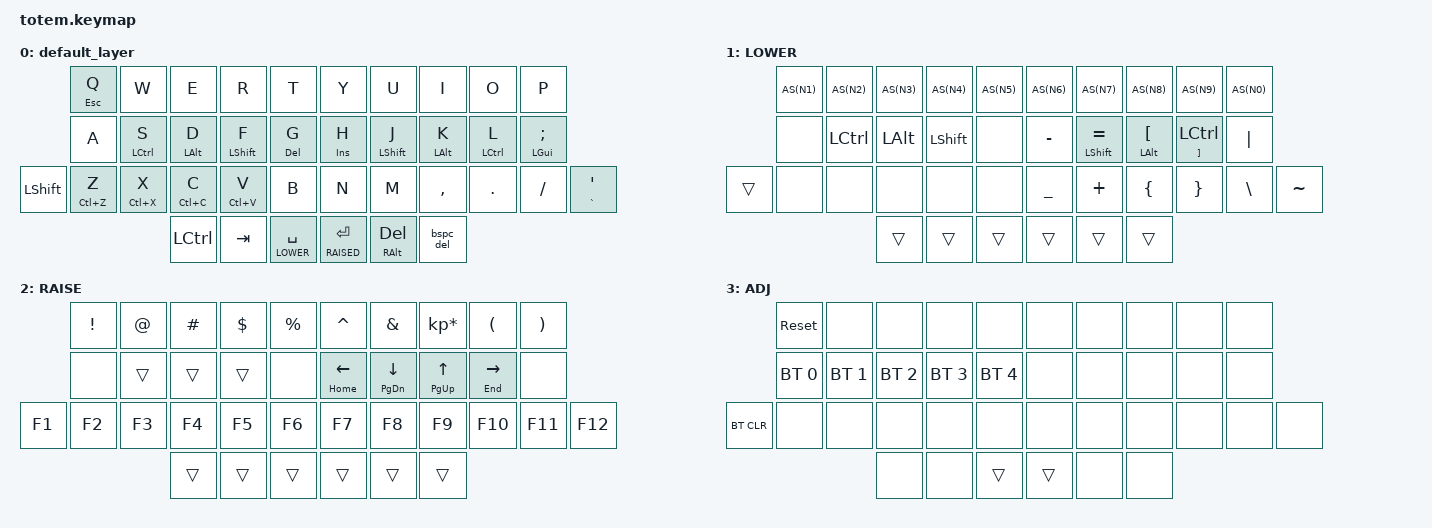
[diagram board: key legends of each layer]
//
//                                                        ▀▀▀▀▀     ▀▀▀▀▀          ▀▀█▀▀
//                                                        ▄▀▀▀▄  ▄  ▄▀▀▀▄  ▄  ▄▀▀▀▄  █  ▄▀▀▀▄
//                                                        █   █  █  █   █  █  █   █  █  █   █
//                                                         ▀▀▀   █   ▀▀▀   █   ▀▀▀   ▀   ▀▀▀
//                                                               █      ▄▄▄█▄▄▄    █   █  
//                                                               ▀      █  █  █     █▄█
//                                                             ▀▀▀▀▀    █  █  █      ▀
//                                                                      ▀  ▀  ▀
//
// ▄▄▄▄▄▄▄▄▄▄▄▄▄▄▄▄▄▄▄▄▄▄▄▄▄▄▄▄▄▄▄▄▄▄▄▄▄▄▄▄▄▄▄▄▄▄▄▄▄▄▄▄▄▄▄▄▄▄▄▄▄▄▄▄▄▄▄▄▄▄▄▄▄▄▄▄▄▄▄▄▄▄▄▄▄▄▄▄▄▄▄▄▄▄▄▄▄▄▄▄▄▄▄▄▄▄▄▄▄▄▄▄▄▄▄▄▄▄▄▄▄▄▄▄▄▄▄▄▄▄▄▄▄▄▄▄▄▄▄▄▄▄▄▄▄▄▄▄▄
       

#include <behaviors.dtsi>
#include <dt-bindings/zmk/keys.h>
#include <dt-bindings/zmk/bt.h>
#include "config.h"
#include "my-behaviours.dtsi"

/ {

     keymap {
                compatible = "zmk,keymap";
// ▄▄▄▄▄▄▄▄▄▄▄▄▄▄▄▄▄▄▄▄▄▄▄▄▄▄▄▄▄▄▄▄▄▄▄▄▄▄▄▄▄▄▄▄▄▄▄▄▄▄▄▄▄▄▄▄▄▄▄▄▄▄▄▄▄▄▄▄▄▄▄▄▄▄▄▄▄▄▄▄▄▄▄▄▄▄▄▄▄▄▄▄▄▄▄▄▄▄▄▄▄▄▄▄▄▄▄▄▄▄▄▄▄▄▄▄▄▄▄▄▄▄▄▄▄▄▄▄▄▄▄▄▄▄▄▄▄▄▄▄▄▄▄▄▄▄▄▄▄

                default_layer {
// ┏━━━━━━━━━━━━━━━━━━━━━━━━━━━━━━━━━━━━━━━┓
//label= "BASE"                              ;
// ┗━━━━━━━━━━━━━━━━━━━━━━━━━━━━━━━━━━━━━━━┛
//             ┏━━━━━━━━━━━┳━━━━━━━━━━━┳━━━━━━━━━━━┳━━━━━━━━━━━┳━━━━━━━━━━━┓   ┏━━━━━━━━━━━┳━━━━━━━━━━━┳━━━━━━━━━━━┳━━━━━━━━━━━┳━━━━━━━━━━━┓
//             ┃   Q/ESC   ┃     W     ┃     E     ┃     R     ┃     T     ┃   ┃     Y     ┃     U     ┃     I     ┃     O     ┃     P     ┃
//             ┣━━━━━━━━━━━╋━━━━━━━━━━━╋━━━━━━━━━━━╋━━━━━━━━━━━╋━━━━━━━━━━━┫   ┣━━━━━━━━━━━╋━━━━━━━━━━━╋━━━━━━━━━━━╋━━━━━━━━━━━╋━━━━━━━━━━━┫
//             ┃     A     ┃  S/LCTRL  ┃   D/LALT  ┃  F/LSHT   ┃     G     ┃   ┃   H/INS   ┃  J/LSHFT  ┃   K/LALT  ┃  L/LCTRL  ┃  ;/LGUI   ┃
// ┏━━━━━━━━━━━╋━━━━━━━━━━━╋━━━━━━━━━━━╋━━━━━━━━━━━╋━━━━━━━━━━━╋━━━━━━━━━━━┫   ┣━━━━━━━━━━━╋━━━━━━━━━━━╋━━━━━━━━━━━╋━━━━━━━━━━━╋━━━━━━━━━━━╋━━━━━━━━━━━┓
// ┃  LSHIFT   ┃     Z     ┃     X     ┃     C     ┃     V     ┃     B     ┃   ┃     N     ┃     M     ┃     ,     ┃     .     ┃     /     ┃    '/`    ┃
// ┗━━━━━━━━━━━┻━━━━━━━━━━━┻━━━━━━━━━━━╋━━━━━━━━━━━╋━━━━━━━━━━━╋━━━━━━━━━━━┫   ┣━━━━━━━━━━━╋━━━━━━━━━━━╋━━━━━━━━━━━╋━━━━━━━━━━━┻━━━━━━━━━━━┻━━━━━━━━━━━┛
//                                     ┃   LCTRL   ┃    TAB    ┃  SPC/LWR  ┃   ┃ ENTER/RSD ┃ DEL/RALT  ┃  BSPC/DEL ┃
//                                     ┗━━━━━━━━━━━┻━━━━━━━━━━━┻━━━━━━━━━━━┛   ┗━━━━━━━━━━━┻━━━━━━━━━━━┻━━━━━━━━━━━┛
 bindings = <
// ╷           ╷           ╷           ╷           ╷           ╷           ╷   ╷               ╷             ╷           ╷            ╷           ╷           ╷

                 &mt ESC Q   &kp W          &kp E       &kp R        &kp T           &kp Y        &kp U        &kp I        &kp O        &kp P       
                 &kp A       &mt LCTRL S    &mt LALT D  &mt LSHIFT F &mt DEL G       &mt INSERT H &mt LSHIFT J &mt LALT K   &mt LCTRL L  &ht LGUI SEMI    
     &kp LSHFT   &ht LC(Z) Z &ht LC(X) X    &ht LC(C) C &ht LC(V) V  &kp B           &kp N        &kp M        &kp COMMA    &kp DOT      &kp FSLH   &ht GRAVE SQT
                                            &kp LCTRL   &kp TAB      &lt LOWER SPACE &lt RAISED RET &mt RALT DEL &bspc_del
                        >;
                };

// ▄▄▄▄▄▄▄▄▄▄▄▄▄▄▄▄▄▄▄▄▄▄▄▄▄▄▄▄▄▄▄▄▄▄▄▄▄▄▄▄▄▄▄▄▄▄▄▄▄▄▄▄▄▄▄▄▄▄▄▄▄▄▄▄▄▄▄▄▄▄▄▄▄▄▄▄▄▄▄▄▄▄▄▄▄▄▄▄▄▄▄▄▄▄▄▄▄▄▄▄▄▄▄▄▄▄▄▄▄▄▄▄▄▄▄▄▄▄▄▄▄▄▄▄▄▄▄▄▄▄▄▄▄▄▄▄▄▄▄▄▄▄▄▄▄▄▄▄▄


                lower_layer {
// ┏━━━━━━━━━━━━━━━━━━━━━━━━━━━━━━━━━━━━━━━┓
label= "LOWER"                              ;
// ┗━━━━━━━━━━━━━━━━━━━━━━━━━━━━━━━━━━━━━━━┛
//             ┏━━━━━━━━━━━┳━━━━━━━━━━━┳━━━━━━━━━━━┳━━━━━━━━━━━┳━━━━━━━━━━━┓   ┏━━━━━━━━━━━┳━━━━━━━━━━━┳━━━━━━━━━━━┳━━━━━━━━━━━┳━━━━━━━━━━━┓
//             ┃     1     ┃     2     ┃      3    ┃     4     ┃     5     ┃   ┃     6     ┃     7     ┃     8     ┃     9     ┃     0     ┃
//             ┣━━━━━━━━━━━╋━━━━━━━━━━━╋━━━━━━━━━━━╋━━━━━━━━━━━╋━━━━━━━━━━━┫   ┣━━━━━━━━━━━╋━━━━━━━━━━━╋━━━━━━━━━━━╋━━━━━━━━━━━╋━━━━━━━━━━━┫
//             ┃     X     ┃   LCTRL   ┃    ALT    ┃   LSHT    ┃     X     ┃   ┃     -     ┃  =/LSHFT  ┃  [/LALT   ┃  ]/LCTRL  ┃     |     ┃
// ┏━━━━━━━━━━━╋━━━━━━━━━━━╋━━━━━━━━━━━╋━━━━━━━━━━━╋━━━━━━━━━━━╋━━━━━━━━━━━┫   ┣━━━━━━━━━━━╋━━━━━━━━━━━╋━━━━━━━━━━━╋━━━━━━━━━━━╋━━━━━━━━━━━╋━━━━━━━━━━━┓
// ┃           ┃     X     ┃    X      ┃     X     ┃     X     ┃     X     ┃   ┃     _     ┃     +     ┃     {     ┃     }     ┃     \     ┃     ~     ┃
// ┗━━━━━━━━━━━┻━━━━━━━━━━━┻━━━━━━━━━━━╋━━━━━━━━━━━╋━━━━━━━━━━━╋━━━━━━━━━━━┫   ┣━━━━━━━━━━━╋━━━━━━━━━━━╋━━━━━━━━━━━╋━━━━━━━━━━━┻━━━━━━━━━━━┻━━━━━━━━━━━┛
//                                     ┃           ┃           ┃           ┃   ┃           ┃           ┃           ┃
//                                     ┗━━━━━━━━━━━┻━━━━━━━━━━━┻━━━━━━━━━━━┛   ┗━━━━━━━━━━━┻━━━━━━━━━━━┻━━━━━━━━━━━┛
 bindings = <
// ╷           ╷           ╷                 ╷              ╷               ╷           ╷   ╷               ╷                ╷                  ╷                 ╷           ╷           ╷

                 AS(N1)         AS(N2)         AS(N3)        AS(N4)            AS(N5)            AS(N6)        AS(N7)            AS(N8)             AS(N9)           AS(N0)    
                 &none          &kp LCTRL      &kp LALT      &kp LSHIFT        &none             &kp MINUS     &mt LSHIFT EQUAL  &mt LALT LBKT      &mt RBKT LCTRL   &kp PIPE 
     &trans      &none          &none          &none         &none             &none             &kp UNDER     &kp PLUS          &kp LBRC           &kp RBRC         &kp BSLH   &kp TILDE
                                               &trans        &trans            &trans            &trans        &trans            &trans
                        >;
                };

// ▄▄▄▄▄▄▄▄▄▄▄▄▄▄▄▄▄▄▄▄▄▄▄▄▄▄▄▄▄▄▄▄▄▄▄▄▄▄▄▄▄▄▄▄▄▄▄▄▄▄▄▄▄▄▄▄▄▄▄▄▄▄▄▄▄▄▄▄▄▄▄▄▄▄▄▄▄▄▄▄▄▄▄▄▄▄▄▄▄▄▄▄▄▄▄▄▄▄▄▄▄▄▄▄▄▄▄▄▄▄▄▄▄▄▄▄▄▄▄▄▄▄▄▄▄▄▄▄▄▄▄▄▄▄▄▄▄▄▄▄▄▄▄▄▄▄▄▄▄


                raise_layer {
// ┏━━━━━━━━━━━━━━━━━━━━━━━━━━━━━━━━━━━━━━━┓
label= "RAISE"                               ;
// ┗━━━━━━━━━━━━━━━━━━━━━━━━━━━━━━━━━━━━━━━┛
//             ┏━━━━━━━━━━━┳━━━━━━━━━━━┳━━━━━━━━━━━┳━━━━━━━━━━━┳━━━━━━━━━━━┓   ┏━━━━━━━━━━━┳━━━━━━━━━━━┳━━━━━━━━━━━┳━━━━━━━━━━━┳━━━━━━━━━━━┓
//             ┃     !     ┃     @     ┃     #     ┃     $     ┃     %     ┃   ┃     ˆ     ┃     &     ┃     *     ┃     (     ┃     )     ┃
//             ┣━━━━━━━━━━━╋━━━━━━━━━━━╋━━━━━━━━━━━╋━━━━━━━━━━━╋━━━━━━━━━━━┫   ┣━━━━━━━━━━━╋━━━━━━━━━━━╋━━━━━━━━━━━╋━━━━━━━━━━━╋━━━━━━━━━━━┫
//             ┃     X     ┃           ┃           ┃           ┃    X      ┃   ┃   L/HOME  ┃   D/PGD   ┃   U/PGU   ┃  R/END    ┃     X     ┃
// ┏━━━━━━━━━━━╋━━━━━━━━━━━╋━━━━━━━━━━━╋━━━━━━━━━━━╋━━━━━━━━━━━╋━━━━━━━━━━━┫   ┣━━━━━━━━━━━╋━━━━━━━━━━━╋━━━━━━━━━━━╋━━━━━━━━━━━╋━━━━━━━━━━━╋━━━━━━━━━━━┓
// ┃    F1     ┃     F2    ┃    F3     ┃    F4     ┃     F5    ┃    F6     ┃   ┃    F7     ┃    F8     ┃     F9    ┃    F10    ┃   F11     ┃    F12    ┃
// ┗━━━━━━━━━━━┻━━━━━━━━━━━┻━━━━━━━━━━━╋━━━━━━━━━━━╋━━━━━━━━━━━╋━━━━━━━━━━━┫   ┣━━━━━━━━━━━╋━━━━━━━━━━━╋━━━━━━━━━━━╋━━━━━━━━━━━┻━━━━━━━━━━━┻━━━━━━━━━━━┛
//                                     ┃           ┃           ┃           ┃   ┃           ┃           ┃           ┃
//                                     ┗━━━━━━━━━━━┻━━━━━━━━━━━┻━━━━━━━━━━━┛   ┗━━━━━━━━━━━┻━━━━━━━━━━━┻━━━━━━━━━━━┛
 bindings = <
// ╷           ╷           ╷           ╷           ╷           ╷           ╷   ╷           ╷                 ╷              ╷             ╷           ╷           ╷

                &kp EXCL     &kp AT       &kp HASH     &kp DLLR    &kp PRCNT      &kp CARET     &kp AMPS       &kp KP_MULTIPLY &kp LPAR      &kp RPAR 
                &none        &trans       &trans       &trans      &none          &ht HOME LEFT &ht PG_DN DOWN &ht PG_UP UP    &ht END RIGHT &none
      &kp F1    &kp F2       &kp F3       &kp F4       &kp F5      &kp F6         &kp F7        &kp F8         &kp F9          &kp F10       &kp F11     &kp F12 
                                          &trans       &trans      &trans         &trans        &trans         &trans
                        >;
                };

// ▄▄▄▄▄▄▄▄▄▄▄▄▄▄▄▄▄▄▄▄▄▄▄▄▄▄▄▄▄▄▄▄▄▄▄▄▄▄▄▄▄▄▄▄▄▄▄▄▄▄▄▄▄▄▄▄▄▄▄▄▄▄▄▄▄▄▄▄▄▄▄▄▄▄▄▄▄▄▄▄▄▄▄▄▄▄▄▄▄▄▄▄▄▄▄▄▄▄▄▄▄▄▄▄▄▄▄▄▄▄▄▄▄▄▄▄▄▄▄▄▄▄▄▄▄▄▄▄▄▄▄▄▄▄▄▄▄▄▄▄▄▄▄▄▄▄▄▄▄


                adjust_layer {
// ┏━━━━━━━━━━━━━━━━━━━━━━━━━━━━━━━━━━━━━━━┓
label= "ADJ"                               ;
// ┗━━━━━━━━━━━━━━━━━━━━━━━━━━━━━━━━━━━━━━━┛
//             ┏━━━━━━━━━━━┳━━━━━━━━━━━┳━━━━━━━━━━━┳━━━━━━━━━━━┳━━━━━━━━━━━┓   ┏━━━━━━━━━━━┳━━━━━━━━━━━┳━━━━━━━━━━━┳━━━━━━━━━━━┳━━━━━━━━━━━┓
//             ┃   RESET   ┃           ┃           ┃           ┃           ┃   ┃           ┃           ┃           ┃           ┃           ┃
//             ┣━━━━━━━━━━━╋━━━━━━━━━━━╋━━━━━━━━━━━╋━━━━━━━━━━━╋━━━━━━━━━━━┫   ┣━━━━━━━━━━━╋━━━━━━━━━━━╋━━━━━━━━━━━╋━━━━━━━━━━━╋━━━━━━━━━━━┫
//             ┃    BT0    ┃   BT1     ┃    BT2    ┃    BT3    ┃   BT4     ┃   ┃           ┃           ┃           ┃           ┃           ┃
// ┏━━━━━━━━━━━╋━━━━━━━━━━━╋━━━━━━━━━━━╋━━━━━━━━━━━╋━━━━━━━━━━━╋━━━━━━━━━━━┫   ┣━━━━━━━━━━━╋━━━━━━━━━━━╋━━━━━━━━━━━╋━━━━━━━━━━━╋━━━━━━━━━━━╋━━━━━━━━━━━┓
// ┃  BT_CLEAR ┃           ┃           ┃           ┃           ┃           ┃   ┃           ┃           ┃           ┃           ┃           ┃           ┃
// ┗━━━━━━━━━━━┻━━━━━━━━━━━┻━━━━━━━━━━━╋━━━━━━━━━━━╋━━━━━━━━━━━╋━━━━━━━━━━━┫   ┣━━━━━━━━━━━╋━━━━━━━━━━━╋━━━━━━━━━━━╋━━━━━━━━━━━┻━━━━━━━━━━━┻━━━━━━━━━━━┛
//                                     ┃           ┃           ┃           ┃   ┃           ┃           ┃           ┃
//                                     ┗━━━━━━━━━━━┻━━━━━━━━━━━┻━━━━━━━━━━━┛   ┗━━━━━━━━━━━┻━━━━━━━━━━━┻━━━━━━━━━━━┛
 bindings = <
// ╷           ╷           ╷           ╷           ╷           ╷           ╷   ╷           ╷           ╷           ╷           ╷           ╷           ╷

                 &sys_reset   &none        &none        &none        &none        &none      &none        &none      &none        &none 
                 &bt BT_SEL 0 &bt BT_SEL 1 &bt BT_SEL 2 &bt BT_SEL 3 &bt BT_SEL 4 &none      &none        &none      &none        &none 
   &bt BT_CLR    &none        &none        &none        &none        &none        &none      &none        &none      &none        &none    &none 
                                           &none        &none        &trans       &trans     &none        &none  
                        >;
                };
        };
};

